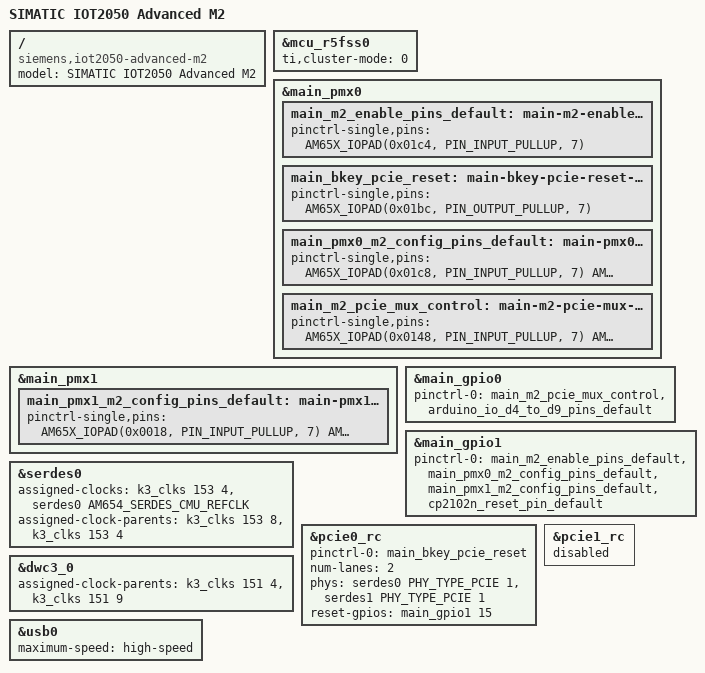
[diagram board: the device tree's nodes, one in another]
#include "k3-am6548-iot2050-advanced-common.dtsi"
#include "k3-am65-iot2050-common-pg2.dtsi"
/ {
	compatible = "siemens,iot2050-advanced-m2", "ti,am654";
	model = "SIMATIC IOT2050 Advanced M2";
};
&mcu_r5fss0 {
	ti,cluster-mode = <0>;
};
&main_pmx0 {
	main_m2_enable_pins_default: main-m2-enable-default-pins {
		pinctrl-single,pins = <
			AM65X_IOPAD(0x01c4, PIN_INPUT_PULLUP, 7)   
		>;
	};
	main_bkey_pcie_reset: main-bkey-pcie-reset-default-pins {
		pinctrl-single,pins = <
			AM65X_IOPAD(0x01bc, PIN_OUTPUT_PULLUP, 7)   
		>;
	};
	main_pmx0_m2_config_pins_default: main-pmx0-m2-config-default-pins {
		pinctrl-single,pins = <
			AM65X_IOPAD(0x01c8, PIN_INPUT_PULLUP, 7)   
			AM65X_IOPAD(0x01cc, PIN_INPUT_PULLUP, 7)   
		>;
	};
	main_m2_pcie_mux_control: main-m2-pcie-mux-control-default-pins {
		pinctrl-single,pins = <
			AM65X_IOPAD(0x0148, PIN_INPUT_PULLUP, 7)   
			AM65X_IOPAD(0x0160, PIN_INPUT_PULLUP, 7)   
			AM65X_IOPAD(0x0164, PIN_INPUT_PULLUP, 7)   
		>;
	};
};
&main_pmx1 {
	main_pmx1_m2_config_pins_default: main-pmx1-m2-config-default-pins {
		pinctrl-single,pins = <
			AM65X_IOPAD(0x0018, PIN_INPUT_PULLUP, 7)   
			AM65X_IOPAD(0x001c, PIN_INPUT_PULLUP, 7)   
		>;
	};
};
&main_gpio0 {
	pinctrl-names = "default";
	pinctrl-0 =
		<&main_m2_pcie_mux_control>,
		<&arduino_io_d4_to_d9_pins_default>;
};
&main_gpio1 {
	pinctrl-names = "default";
	pinctrl-0 =
		<&main_m2_enable_pins_default>,
		<&main_pmx0_m2_config_pins_default>,
		<&main_pmx1_m2_config_pins_default>,
		<&cp2102n_reset_pin_default>;
};
&serdes0 {
	assigned-clocks = <&k3_clks 153 4>, <&serdes0 AM654_SERDES_CMU_REFCLK>;
	assigned-clock-parents = <&k3_clks 153 8>, <&k3_clks 153 4>;
};
&pcie0_rc {
	pinctrl-names = "default";
	pinctrl-0 = <&main_bkey_pcie_reset>;
	num-lanes = <2>;
	phys = <&serdes0 PHY_TYPE_PCIE 1>, <&serdes1 PHY_TYPE_PCIE 1>;
	phy-names = "pcie-phy0","pcie-phy1";
	reset-gpios = <&main_gpio1 15 GPIO_ACTIVE_HIGH>;
	status = "okay";
};
&pcie1_rc {
	status = "disabled";
};
&dwc3_0 {
	assigned-clock-parents = <&k3_clks 151 4>,   
				 <&k3_clks 151 9>;   
	/delete-property/ phys;
	/delete-property/ phy-names;
};
&usb0 {
	maximum-speed = "high-speed";
	/delete-property/ snps,dis-u1-entry-quirk;
	/delete-property/ snps,dis-u2-entry-quirk;
};
